# RL6678_IP_SVD register map
Vendor: Realtek
Registers are 32-bit, read-write, reset 0x0 unless marked. A register's access mark holds for its fields unless they carry their own. Offsets are from the block's base; [hi:lo] are bit positions; {n}, {i} and the like mark numbered series.

## VAD_REG
Base 0x4100C000
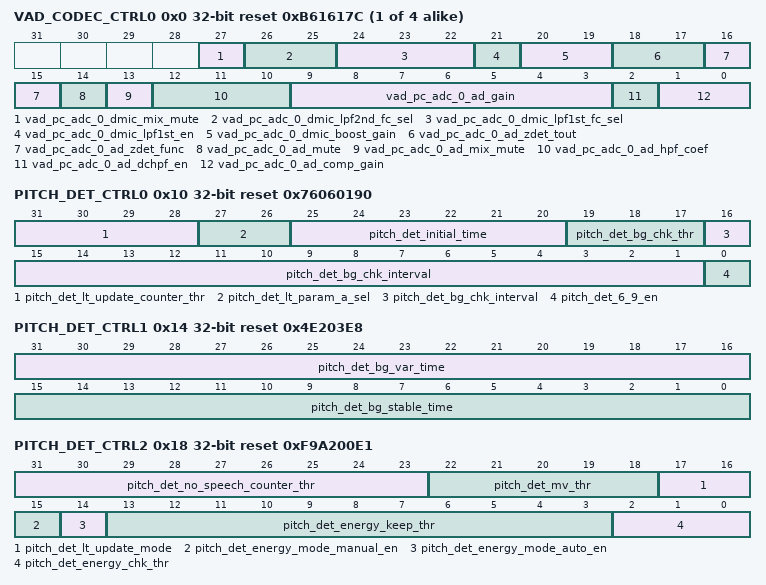
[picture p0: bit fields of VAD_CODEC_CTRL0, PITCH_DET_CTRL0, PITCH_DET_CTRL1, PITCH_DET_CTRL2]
{0x0+4i} VAD_CODEC_CTRL{i} reset 0xB61617C (i=0..3) — VAD CODEC Control Register {i}
  [27] vad_pc_adc_{i}_dmic_mix_mute — DMIC input path mute control 0: Unmute 1: Mute
  [26:25] vad_pc_adc_{i}_dmic_lpf2nd_fc_sel — DMIC SRC 2nd LPF fc (-3dB)
  [24:22] vad_pc_adc_{i}_dmic_lpf1st_fc_sel — DMIC SRC 1st LPF fc (-3dB)
  [21] vad_pc_adc_{i}_dmic_lpf1st_en — DMIC SRC in AD filter 1st LPF control 0: disable 1: enable
  [20:19] vad_pc_adc_{i}_dmic_boost_gain — ADC digital boost gain 2'b00: 0dB 2'b01: 10dB 2'b10: 20dB 2'b11: 30dB
  [18:17] vad_pc_adc_{i}_ad_zdet_tout — ADC zero detection time out select 2'b00: 1024*16 samples 2'b01: 1024*32 samples 2'b10: 1024*64 samples 2'b11: 64 samples
  [16:15] vad_pc_adc_{i}_ad_zdet_func — ADC zero detection function select 2'b00: immediate change 2'b01: zero detection & immediate change 2'b10: zero detection & increase/decrease change 2'b11: unchange
  [14] vad_pc_adc_{i}_ad_mute — Digital Mute at Digital Volme 0: Unmute 1: Mute
  [13] vad_pc_adc_{i}_ad_mix_mute — analog ADC input path mute control 0: Unmute 1: Mute
  [12:10] vad_pc_adc_{i}_ad_hpf_coef — High pass filter coefficient selection (3dB point/sampling rate) 3'b000: 2^-13 (0.3Hz/16k) 3'b001: 2^-12 (0.6Hz/16k) 3'b010: 2^-11 (1.2Hz/16k) 3'b011: 2^-10 (2.5Hz/16k) 3'b100: 2^-9 (5Hz/16k) 3'b101: 2^-8 (10Hz/16k) 3'b110: 2^-7 (20Hz/16k) 3'b111: 2^-6 (40Hz/16k)
  [9:3] vad_pc_adc_{i}_ad_gain — ADC digital volume in 0.375dB step, -17.625dB ~ 30dB 7'h00: -17.625dB ... 7'h2f: 0dB 7'h30: 0.375dB ... 7'h7f: 30dB
  [2] vad_pc_adc_{i}_ad_dchpf_en — High pass filter enable control 1'b0: disable 1'b1: enable
  [1:0] vad_pc_adc_{i}_ad_comp_gain — ADC compensate gain 2'b00: 0dB 2'b01: 1dB 2'b10: 2dB 2'b11: 3dB
0x10 PITCH_DET_CTRL0 reset 0x76060190 — Pitch Detection Control Register 0
  [31:28] pitch_det_lt_update_counter_thr — Counter threshold of long_term energy to update no speech segment
  [27:26] pitch_det_lt_param_a_sel — The coefficient of long_term energy calculation 0: 2^-4 1: 2^-5 2: 2^-6 3: 2^-4
  [25:20] pitch_det_initial_time — Initial time after rst_n check time = REG * 4ms
  [19:17] pitch_det_bg_chk_thr — The threshold for checking the potential energy variation in background.
  [16:1] pitch_det_bg_chk_interval — The time for checking the energy variation in background when potential energy variation detected check time = REG * 4ms
  [0] pitch_det_6_9_en — Enable signale for selection of the harmonics pattern 6&9 0: disable 1: enbale
0x14 PITCH_DET_CTRL1 reset 0x4E203E8 — Pitch Detection Control Register 1
  [31:16] pitch_det_bg_var_time — The accumulated time when pitch_det_bg_chk_interval keeps checking check time = REG * 4ms
  [15:0] pitch_det_bg_stable_time — The check time when there is no potential energy variation in background. check time = REG * 4ms
0x18 PITCH_DET_CTRL2 reset 0xF9A200E1 — Pitch Detection Control Register 2
  [31:23] pitch_det_no_speech_counter_thr — Counter threshold to monitor how long there is no speech occurrence
  [22:18] pitch_det_mv_thr — Threshold of majority vote to determine whether the speech features appear Range: 4'h0 ~ 4'h13
  [17:16] pitch_det_lt_update_mode — 3 modes for lt_update 0: always update 1: for RTL simulation 2: follow initial procedural 3: follow initial procedural
  [15] pitch_det_energy_mode_manual_en — Enable signal of manual selection energy mode 0: disable 1: enable
  [14] pitch_det_energy_mode_auto_en — Enable signal of auto selection energy mode 0: disable 1: enable
  [13:3] pitch_det_energy_keep_thr — The accumulated time when pitch_det_energy_chk_thr keeps checking check time = REG * 4ms
  [2:0] pitch_det_energy_chk_thr — The threshold for checking the potential energy variation in voice
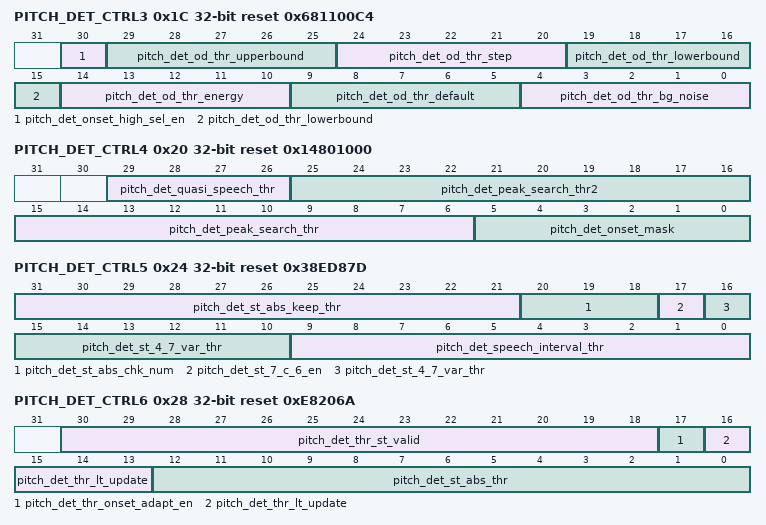
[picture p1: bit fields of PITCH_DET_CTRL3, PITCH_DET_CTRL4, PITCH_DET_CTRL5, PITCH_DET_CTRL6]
0x1C PITCH_DET_CTRL3 reset 0x681100C4 — Pitch Detection Control Register 3
  [30] pitch_det_onset_high_sel_en — Enable signal for onset_high function 0: disable 1: enable
  [29:25] pitch_det_od_thr_upperbound — Upperbound threshold of onset detection
  [24:20] pitch_det_od_thr_step — Threshold step for onset detection threshold update
  [19:15] pitch_det_od_thr_lowerbound — Lowerbound threshold of onset detection
  [14:10] pitch_det_od_thr_energy — Energy mode threshold of onset detection
  [9:5] pitch_det_od_thr_default — Default threshold of onset detection
  [4:0] pitch_det_od_thr_bg_noise — bg_noise threshold of onset detection
0x20 PITCH_DET_CTRL4 reset 0x14801000 — Pitch Detection Control Register 4
  [29:26] pitch_det_quasi_speech_thr — Threshold to determine quasi speech occurrence Range: 4'h0 ~ 4'h7
  [25:16] pitch_det_peak_search_thr2 — Higher threshold for peak search
  [15:6] pitch_det_peak_search_thr — Threshold for peak search
  [5:0] pitch_det_onset_mask — Force the onset output of each subband to 1 6'h00_0001: force the onset output of subband 1 to 1 6'h00_0010: force the onset output of subband 2 to 1 6'h00_0100: force the onset output of subband 3 to 1 6'h00_1000: force the onset output of subband 4 to 1 6'h01_0000: force the onset output of subband 5 to 1 6'h10_0000: force the onset output of subband 6 to 1
0x24 PITCH_DET_CTRL5 reset 0x38ED87D — Pitch Detection Control Register 5
  [31:21] pitch_det_st_abs_keep_thr — The accumulated time when pitch_det_st_abs_chk_num keeps checking check time = REG * 4ms
  [20:18] pitch_det_st_abs_chk_num — The threshold for checking the absolute energy variation
  [17] pitch_det_st_7_c_6_en — Enable control of comparison between st_6 & st_7 for high pitch case
  [16:10] pitch_det_st_4_7_var_thr — The threshold for checking the energy variation in subband 4~7
  [9:0] pitch_det_speech_interval_thr — The time interval for pitch_det_flag to decide the non-speech data after pitch_det_flag_hold is high check time = REG * 4ms
0x28 PITCH_DET_CTRL6 reset 0xE8206A — Pitch Detection Control Register 6
  [30:18] pitch_det_thr_st_valid — Threshold to determine the validation of short_term energy Range: 2^-9 ~ 2^-21
  [17] pitch_det_thr_onset_adapt_en — Enable signal of adaptive onset threshold update 0: disable, the value of onset threshold is fixed at pitch_det_od_thr_default 1: enable
  [16:13] pitch_det_thr_lt_update — Threshold for long_term energy update
  [12:0] pitch_det_st_abs_thr — The threshold of absolute energy Range: 2^-9 ~ 2^-21
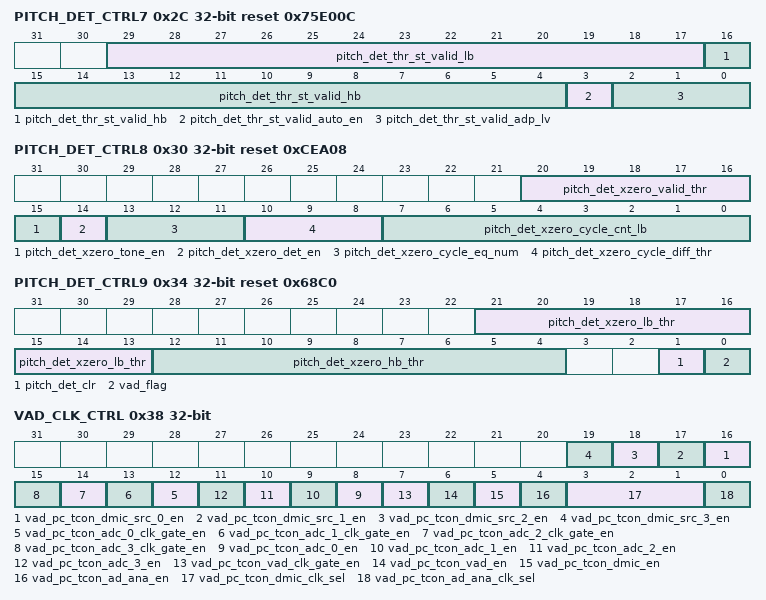
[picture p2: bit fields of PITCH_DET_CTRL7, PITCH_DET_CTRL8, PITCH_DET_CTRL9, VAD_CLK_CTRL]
0x2C PITCH_DET_CTRL7 reset 0x75E00C — Pitch Detection Control Register 7
  [29:17] pitch_det_thr_st_valid_lb — The lower bound for auto thr_st_valid Range: 2^-9 ~ 2^-21
  [16:4] pitch_det_thr_st_valid_hb — The higher bound for auto thr_st_valid Range: 2^-9 ~ 2^-21
  [3] pitch_det_thr_st_valid_auto_en — Auto thr_st_valid enable control 0: disable 1: enable
  [2:0] pitch_det_thr_st_valid_adp_lv — The level control for auto thr_st_valid 0: *2 1: /1 2: /2 3: /4 4: /8 5: /16 6: /32 7: /64
0x30 PITCH_DET_CTRL8 reset 0xCEA08 — Pitch Detection Control Register 8
  [20:16] pitch_det_xzero_valid_thr — The thr for the number of valid xzero frame Range: 5'h0 ~ 5'h13
  [15] pitch_det_xzero_tone_en — Tone detection enable control 0: disable 1: enable
  [14] pitch_det_xzero_det_en — xzero detection enable control 0: disable 1: ebable
  [13:11] pitch_det_xzero_cycle_eq_num — The number of equivalent cycles Range: 3'h0 ~ 3'h5
  [10:8] pitch_det_xzero_cycle_diff_thr — The tolerance of the difference among cycles
  [7:0] pitch_det_xzero_cycle_cnt_lb — The lower bound for the cycle among xzeros
0x34 PITCH_DET_CTRL9 access per field reset 0x68C0 — Pitch Detection Control Register 9
  [21:13] pitch_det_xzero_lb_thr rw — The lower bound of valid number of xzero
  [12:4] pitch_det_xzero_hb_thr rw — The higher bound of valid number of xzero
  [1] pitch_det_clr wo — Clear VAD flag 0: Bypass vad flag 1: Clear vad flag (force output = 0)
  [0] vad_flag ro — VAD flag 0: detection on-going 1: hit
0x38 VAD_CLK_CTRL — VAD Clock Control Register
  [n+16] vad_pc_tcon_dmic_src_{n}_en (n=0..3) — ADC filter {n} dmic LPF control 1'b0: disable 1'b1: enable
  [n+12] vad_pc_tcon_adc_{n}_clk_gate_en (n=0..3) — ADC filter {n} clock control 1'b0: normal 1'b1: gated clock
  [n+8] vad_pc_tcon_adc_{n}_en (n=0..3) — ADC filter {n} control 1'b0: disable 1'b1: enable
  [7] vad_pc_tcon_vad_clk_gate_en — PC vad clock control 1'b0: normal 1'b1: gated clock
  [6] vad_pc_tcon_vad_en — PC vad control 1'b0: disable 1'b1: enable
  [5] vad_pc_tcon_dmic_en — dmic clock control 1'b0: disable 1'b1: enable
  [4] vad_pc_tcon_ad_ana_en — Analog ADC clock control 1'b0: disable 1'b1: enable
  [3:1] vad_pc_tcon_dmic_clk_sel — Select dmic clock 3'b000: 2MHz 3'b001: 1MHz 3'b010: 500KHz 3'b011: 250KHz 3'b100: 125KHz Others: reserved
  [0] vad_pc_tcon_ad_ana_clk_sel — Select analog ADC clock 1'b0: 4MHz 1'b1: 2MHz
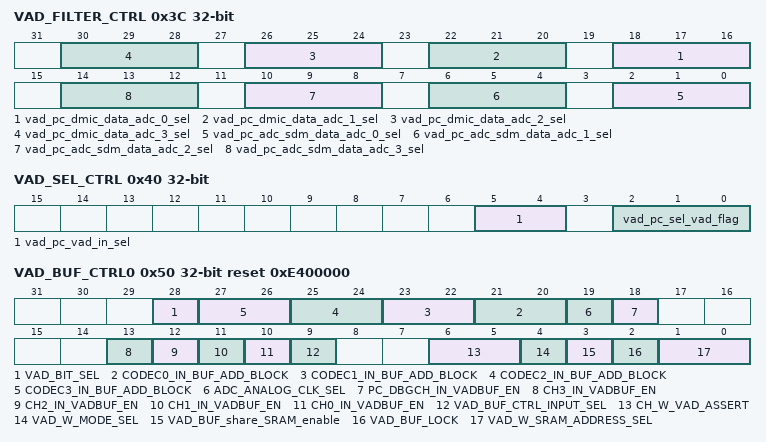
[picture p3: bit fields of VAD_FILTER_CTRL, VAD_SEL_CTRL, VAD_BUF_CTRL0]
0x3C VAD_FILTER_CTRL — VAD Filter Control Register
  [4n+18:4n+16] vad_pc_dmic_data_adc_{n}_sel (n=0..3) — ADC filter {n} dmic data selection 3'b000: DMIC0 3'b001: DMIC1 3'b010: DMIC2 3'b011: DMIC3 3'b100: DMIC4 3'b101: DMIC5 3'b110: DMIC6 3'b111: DMIC7
  [4n+2:4n] vad_pc_adc_sdm_data_adc_{n}_sel (n=0..3) — ADC filter {n} sdm data selection 3'b000: ADC0 3'b001: ADC1 3'b010: ADC2 3'b011: ADC3 3'b100: ADC4 Others: reserved
0x40 VAD_SEL_CTRL — VAD Selection Control Register
  [5:4] vad_pc_vad_in_sel — Select the input source of vad 2'b00: adc_0_out 2'b01: adc_1_out 2'b10: adc_2_out 2'b11: adc_3_out
  [2:0] vad_pc_sel_vad_flag — Select vad flag Source 3'b000: pitch_det_flag_hold 3'b001: pitch_det_flag 3'b010: vad_energy 3'b011: sel_vad_energy 3'b100: vad_abs_flag 3'b101: vad_abs_flag_hold Others: reserved
0x50 VAD_BUF_CTRL0 access per field reset 0xE400000 — VAD Buffer Control Register 0
  [28] VAD_BIT_SEL rw — 0: 16 bits 1: 24 bits By default, 16 bits are used, data performance meets KWS requirements, and 24 bits are reserved.
  [2n+21:2n+20] CODEC{n}_IN_BUF_ADD_BLOCK rw (n=0..3) — When block Mode is in use, four coDEC write addresses are configured to be distributed according to specs. If it is greater than 1CH, set the address to be adjacent. At Interleaving Mode, the order in which the CODEC channel writes to SRAM is configured, and it is recommended that it be stored in that order. 0: A 1: B 2: C 3: D
  [19] ADC_ANALOG_CLK_SEL rw — 0: AUDIO CODEC 1: PC_VAD CODEC
  [18] PC_DBGCH_IN_VADBUF_EN rw — Vad_pc Debug Channel CODEC data sent to VAD_BUF 2channel, one is data, one is flag, debug mode multiplexes CH0/CH1 write SRAM entry address 0: Disable 1: Enable
  [13] CH3_IN_VADBUF_EN rw — Enable VAD CODEC CH3 data to be sent to VAD BUF 0: Disable 1: Enable
  [12] CH2_IN_VADBUF_EN rw — Enable VAD CODEC CH2 data to be sent to VAD BUF 0: Disable 1: Enable
  [11] CH1_IN_VADBUF_EN rw — Enable VAD CODEC C1 data to be sent to VAD BUF 0: Disable 1: Enable
  [10] CH0_IN_VADBUF_EN rw — Enable VAD CODEC CH0 data to be sent to VAD BUF 0: Disable 1: Enable
  [9] VAD_BUF_CTRL_INPUT_SEL rw — The data source used to select VAD_BUF_CTRL is used to switch CLK of writing SRAM, 4M at VAD_PC and 40M at VAD_BT through this bit. 0: VAD_PC 1: VAD_BT
  [6:5] CH_W_VAD_ASSERT ro — The writing channel number when VAD asserts, this status bit is used to record the channel number being written by VAD_BUF_CTRL while VAD is valid. 0: CH0 1: CH1 2: CH2 3: CH3
  [4] VAD_W_MODE_SEL rw — VAD BUF CTRL the way to write VAD BUF 0: Block 1: Interleaving
  [3] VAD_BUF_share_SRAM_enable rw — Whether to occupy the space control bit of SRAM 0: Disable 1: Enable
  [2] VAD_BUF_LOCK rw — 0: Not locked 1: Locked Note: When the bit writes 0, the bit[1:0] can be modified during the working process of the system;When the BIT writes 1, the bit[1:0] cannot be modified during the working process of the system. Only when the whole system is powered on can it be modified again.
  [1:0] VAD_W_SRAM_ADDRESS_SEL rw — 00: 32KB 01: 64KB 10: 96KB 11: 128KB
0x54 VAD_ASSERT_W_SRAM_ADDRSS ro — VAD Assert Writing SRAM Address Register
  [31:0] VAD_ASSERT_W_SRAM_ADDRSS — This address is the current address for writing SRAM when VAD asserts
0x5C BUF_CTRL_W_ADDRESS ro — Buffer Control Write SRAM Address Register
  [31:0] BUF_CTRL_W_ADDRESS — Record VAD_BUF_CTRL write SRAM address. When MCU reads VAD_BUF data, refer to this address to avoid reading the wrong data
0x60 AUDIO_TEST
  [1:0] AUDIO_TEST_SUBMOD — 00: audio ADC output test 01: audio DAC input test 1x: audio codec test
